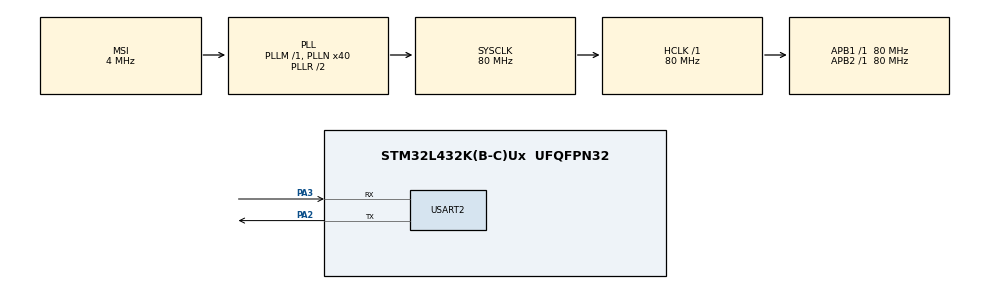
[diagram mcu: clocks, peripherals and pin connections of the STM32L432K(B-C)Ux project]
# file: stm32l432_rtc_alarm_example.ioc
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Mcu.Family=STM32L4
Mcu.Name=STM32L432K(B-C)Ux
Mcu.Package=UFQFPN32
NVIC.PriorityGroup=NVIC_PRIORITYGROUP_4
NVIC.RTC_Alarm_IRQn=true\:0\:0\:false\:false\:true\:true\:true
PA2.Mode=Asynchronous
PA2.Signal=USART2_TX
PA3.Mode=Asynchronous
PA3.Signal=USART2_RX
ProjectManager.HeapSize=0x200
ProjectManager.StackSize=0x400
ProjectManager.TargetToolchain=STM32CubeIDE
RCC.AHBFreq_Value=80000000
RCC.APB1Freq_Value=80000000
RCC.APB1TimFreq_Value=80000000
RCC.APB2Freq_Value=80000000
RCC.APB2TimFreq_Value=80000000
RCC.CortexFreq_Value=80000000
RCC.HCLKFreq_Value=80000000
RCC.HSE_VALUE=8000000
RCC.HSI48_VALUE=48000000
RCC.HSI_VALUE=16000000
RCC.LSE_VALUE=32768
RCC.MSI_VALUE=4000000
RCC.PLLN=40
RCC.SYSCLKFreq_VALUE=80000000
RCC.SYSCLKSource=RCC_SYSCLKSOURCE_PLLCLK
RCC.VCOOutputFreq_Value=160000000
RTC.Alarm=RTC_ALARM_A
RTC.AlarmDateWeekDaySel=RTC_ALARMDATEWEEKDAYSEL_WEEKDAY
RTC.AlarmMaskDateWeekDay=RTC_ALARMMASK_DATEWEEKDAY
RTC.AlarmSubSecondMask=RTC_ALARMSUBSECONDMASK_NONE
RTC.Date=2
RTC.Format=RTC_FORMAT_BIN
RTC.Hours=17
RTC.Hours_A=17
RTC.Minutes=45
RTC.Minutes_A=45
RTC.Seconds_A=59
RTC.Year=20
USART2.VirtualMode-Asynchronous=VM_ASYNC
VP_RTC_VS_RTC_Activate.Mode=RTC_Enabled
VP_RTC_VS_RTC_Alarm_A_Intern.Mode=Alarm A
VP_RTC_VS_RTC_Calendar.Mode=RTC_Calendar
board=custom

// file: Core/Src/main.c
/* USER CODE BEGIN Header */
/**
  ******************************************************************************
  * @file           : main.c
  * @brief          : Main program body
  ******************************************************************************
  * @attention
  *
  * <h2><center>&copy; Copyright (c) 2020 STMicroelectronics.
  * All rights reserved.</center></h2>
  *
  * This software component is licensed by ST under BSD 3-Clause license,
  * the "License"; You may not use this file except in compliance with the
  * License. You may obtain a copy of the License at:
  *                        opensource.org/licenses/BSD-3-Clause
  *
  ******************************************************************************
  */
/* USER CODE END Header */
#include "main.h"
#include "rtc.h"
#include "usart.h"
#include "gpio.h"

/* USER CODE BEGIN Includes */
#include <stdio.h>
#include <string.h>
#include <stdlib.h>
/* USER CODE END Includes */

/* USER CODE BEGIN PV */
extern UART_HandleTypeDef huart2;
int _write(int file, char *data, int len)
{
  HAL_StatusTypeDef status = HAL_UART_Transmit(&huart2, (uint8_t*)data, len, 1000);
  return (status == HAL_OK ? len : 0);
}
/* USER CODE END PV */

void SystemClock_Config(void);

/* USER CODE BEGIN 0 */
static uint16_t count_split(uint8_t *buffer, uint16_t len, uint8_t delim);
static uint8_t *split_str(uint8_t *buffer, uint16_t len, uint16_t pos, uint8_t delim);
uint8_t strings[] = "100|200|300|400|500|600|700|800|900|1111|2222|3333|44444|55555|66666|77777|888888|99999|";
/* USER CODE END 0 */

int main(void)
{

  /* MCU Configuration--------------------------------------------------------*/

  /* Reset of all peripherals, Initializes the Flash interface and the Systick. */
  HAL_Init();

  /* Configure the system clock */
  SystemClock_Config();

  /* Initialize all configured peripherals */
  MX_GPIO_Init();
  MX_RTC_Init();
  MX_USART2_UART_Init();
  /* USER CODE BEGIN 2 */
  printf("Hello STM32L412 !!\r\n");

  uint16_t d_count;
  d_count = count_split(strings, strlen((char *)strings), '|');

  for(int i=0; i<d_count;i++)
  {
    printf("%d\r\n", atoi((char *)split_str(strings, strlen((char *)strings), i,'|')));
  }
  /* USER CODE END 2 */

  /* Infinite loop */
  while (1)
  {

  }
}

void SystemClock_Config(void)
{
  RCC_OscInitTypeDef RCC_OscInitStruct = {0};
  RCC_ClkInitTypeDef RCC_ClkInitStruct = {0};
  RCC_PeriphCLKInitTypeDef PeriphClkInit = {0};

  /** Initializes the RCC Oscillators according to the specified parameters
  * in the RCC_OscInitTypeDef structure.
  */
  RCC_OscInitStruct.OscillatorType = RCC_OSCILLATORTYPE_LSI|RCC_OSCILLATORTYPE_MSI;
  RCC_OscInitStruct.LSIState = RCC_LSI_ON;
  RCC_OscInitStruct.MSIState = RCC_MSI_ON;
  RCC_OscInitStruct.MSICalibrationValue = 0;
  RCC_OscInitStruct.MSIClockRange = RCC_MSIRANGE_6;
  RCC_OscInitStruct.PLL.PLLState = RCC_PLL_ON;
  RCC_OscInitStruct.PLL.PLLSource = RCC_PLLSOURCE_MSI;
  RCC_OscInitStruct.PLL.PLLM = 1;
  RCC_OscInitStruct.PLL.PLLN = 40;
  RCC_OscInitStruct.PLL.PLLP = RCC_PLLP_DIV7;
  RCC_OscInitStruct.PLL.PLLQ = RCC_PLLQ_DIV2;
  RCC_OscInitStruct.PLL.PLLR = RCC_PLLR_DIV2;
  if (HAL_RCC_OscConfig(&RCC_OscInitStruct) != HAL_OK)
  {
    Error_Handler();
  }
  /** Initializes the CPU, AHB and APB buses clocks
  */
  RCC_ClkInitStruct.ClockType = RCC_CLOCKTYPE_HCLK|RCC_CLOCKTYPE_SYSCLK
                              |RCC_CLOCKTYPE_PCLK1|RCC_CLOCKTYPE_PCLK2;
  RCC_ClkInitStruct.SYSCLKSource = RCC_SYSCLKSOURCE_PLLCLK;
  RCC_ClkInitStruct.AHBCLKDivider = RCC_SYSCLK_DIV1;
  RCC_ClkInitStruct.APB1CLKDivider = RCC_HCLK_DIV1;
  RCC_ClkInitStruct.APB2CLKDivider = RCC_HCLK_DIV1;

  if (HAL_RCC_ClockConfig(&RCC_ClkInitStruct, FLASH_LATENCY_4) != HAL_OK)
  {
    Error_Handler();
  }
  PeriphClkInit.PeriphClockSelection = RCC_PERIPHCLK_RTC|RCC_PERIPHCLK_USART2;
  PeriphClkInit.Usart2ClockSelection = RCC_USART2CLKSOURCE_PCLK1;
  PeriphClkInit.RTCClockSelection = RCC_RTCCLKSOURCE_LSI;
  if (HAL_RCCEx_PeriphCLKConfig(&PeriphClkInit) != HAL_OK)
  {
    Error_Handler();
  }
  /** Configure the main internal regulator output voltage
  */
  if (HAL_PWREx_ControlVoltageScaling(PWR_REGULATOR_VOLTAGE_SCALE1) != HAL_OK)
  {
    Error_Handler();
  }
}

/* USER CODE BEGIN 4 */
extern RTC_HandleTypeDef hrtc;
void HAL_RTC_AlarmAEventCallback(RTC_HandleTypeDef *rtc)
{
  RTC_DateTypeDef sdatestructureget;
  RTC_TimeTypeDef stimestructureget;

  /* Get the RTC current Time */
  HAL_RTC_GetTime(&hrtc, &stimestructureget, RTC_FORMAT_BIN);
  /* Get the RTC current Date */
  HAL_RTC_GetDate(&hrtc, &sdatestructureget, RTC_FORMAT_BIN);
  /* Display time Format : hh:mm:ss */
  printf("%02d:%02d:%02d\r\n",stimestructureget.Hours, stimestructureget.Minutes, stimestructureget.Seconds);
}

static uint16_t count_split(uint8_t *buffer, uint16_t len, uint8_t delim)
{
  uint16_t count = 0;

  if(len == 0)
    return 0;

  for(int i=0; i<len; i++)
  {
    if(buffer[i] == delim)
      count++;
  }

  if((buffer[len-1] != delim) && (count > 0))
    count++;

  return count;
}

static uint8_t *split_str(uint8_t *buffer, uint16_t len, uint16_t pos, uint8_t delim)
{
  uint16_t temp_pos=0;
  uint8_t *temp_ptr = buffer;

  for(int i=0; i<len; i++)
  {
    if(buffer[i] == delim)
    {
      if(temp_pos == pos)
        return temp_ptr;
      else
      {
        if((i+1) < len)
          temp_ptr = &buffer[i+1];
      }
      temp_pos++;
    }
  }

  return temp_ptr;
}
/* USER CODE END 4 */

void Error_Handler(void)
{
}

/************************ (C) COPYRIGHT STMicroelectronics *****END OF FILE****/
